# TC37XPD register map
Vendor: Infineon; Series: ATVMC; File version: 100
CPU: other r0p0, little endian, MPU, FPU, vendor SysTick, 4 interrupt priority bits
Registers are 32-bit, read-write, reset 0x0 unless marked. A register's access mark holds for its fields unless they carry their own. Offsets are from the block's base; [hi:lo] are bit positions; lines under a group give offsets from that group; {n}, {i} and the like mark numbered series.

## GTM (part 5 of 13)
Base 0xF0100000
0x28000 DPLL group
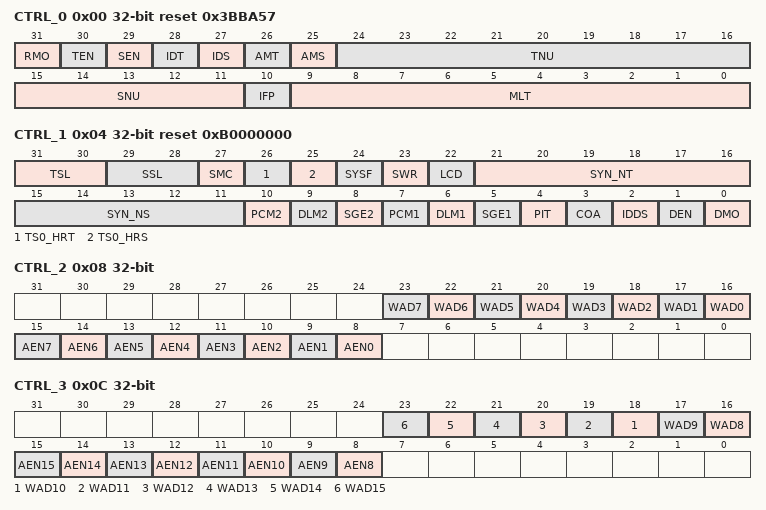
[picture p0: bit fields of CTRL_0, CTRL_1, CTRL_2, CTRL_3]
  0x00 CTRL_0 reset 0x3BBA57 — DPLL Control Register 0 resetvalue={Application Reset:0x3BBA57}
    [31] RMO — Reference mode. CROSSREFERENCE CROSSREFERENCE Selection of the relevant input signal for generation of SUB INC1. Double synchronous mode for SMC 1 Signal TRIGGER is used to generate the SUB INC1 signals and STATE is used to generate the SUB INC2 signals. Note For SMC 0 TRIGGER and STATE are prepared to calculate SUB INC1. The RMO bit gives a decision only which of them is used. For changing from normal mode to emergency mode at the following TRIGGER slope according to the RMO value in the shadow register CROSSREFERENCE the PSSC value is calculated by PSSC PSSM correction value forward direction or PSSC PSSM correction value backward direction with the correction value inc cnt1 nmb t. For changing from emergency mode to normal mode at the following STATE slope according to the RMO value in the shadow register CROSSREFERENCE the PSTC value is calculated by PSTC PSTM correction value forward direction or PSTC PSTM correction value backward direction with the correction value inc cnt1 nmb s. In case no further TRIGGER or STATE events the CPU has to perform the above corrections.
    [30] TEN — TRIGGER enable
    [29] SEN — STATE enable
    [28] IDT — Input delay TRIGGER. CROSSREFERENCE Use of input delay information transmitted in FT part of the TRIGGER signal.
    [27] IDS — Input delay STATE. CROSSREFERENCE Use of input delay information transmitted in FT part of the STATE signal.
    [26] AMT — Adapt mode TRIGGER. CROSSREFERENCE Use of adaptation information of TRIGGER.
    [25] AMS — Adapt mode STATE. CROSSREFERENCE Use of adaptation information of STATE.
    [24:16] TNU — TRIGGER number. CROSSREFERENCE TNU 1 is number of nominal TRIGGER events in HALF SCALE 1...512 . Note The number of nominal TRIGGER events is the decimal value plus 1.This value can only be written when RMO 1 and SMC 0 or DEN 0. To make sure that this signal is not changed during a mode change RMO 0 means that the status of RMO 0 must be given before and during writing to the register. Set TSL 00 before changing this value and set RMO 0 only after FULL SCALE with TSL gt 0.
    [15:11] SNU — STATE number. For IFP 1 the time between two active TRIGGER or STATE events must be always greater then 2.34 ms and the value x of MLT MLS1 or MLS2 must be chosen such that the number of time stamp pulses between two SUB INC events must be less than 65536. This is fulfilled when x is greater than 256. SNU 1 is number of nominal STATE events in HALF SCALE 1...32 . The number of nominal STATE events is the decimal value plus 1. This value can only be written when RMO 0 and SMC 0 or DEN 0. To make sure that this signal is not changed during a mode change RMO 0 means that the status of RMO 0 must be given before and during writing to the register. Set SSL 00 before changing this value and set RMO 1 only after FULL SCALE with SSL gt 0. This register can only be written when DPLL CTRL 11.STATE EXT is not set. If DPLL CTRL 11.STATE EXT is set the signal cannot be written the read value is zero.
    [10] IFP — Input filter position. CROSSREFERENCE stored in an independent shadow register for an active STATE event and for DEN 1. T he time between two active STATE or TRIGGER events must be always greater then 23.4 181 s in addition the TS CLK and the resolution must be chosen such that for each nominal increment the time stamps at the beginning and the end of the increment differ at least in the value of 257. Value contains position or time related information.
    [9:0] MLT — Multiplier for TRIGGER. stored in an independent shadow register for an active TRIGGER event and for DEN 1. MLT 1 is number of SUB INC1 pulses between two TRIGGER events in normal mode 1...1024 Note For emergency mode the number of SUB INC1 pulses between two STATE events is calculated by the CPU using the formula MLS1 MLT 1 TNU 1 SNU 1 in order to get the same number of SUB INC1 pulses for FULL SCALE. This value is stored in RAM at 0x05C0. Change of MLT by the CPU must result in the corresponding change of MLS1 by the CPU for SMC 0. Note The number of MLT events is the binary value plus 1. The value MLT 1 is replaced by MLS1 in the case of SMC 1 see DPLL CTRL 1 register for all relevant calculations.
  0x04 CTRL_1 reset 0xB0000000 — DPLL Control Register 1 resetvalue={Application Reset:0x0B0000000}
    [31:30] TSL — TRIGGER slope select. Definition of active slope for signal TRIGGER each active slope is an event defined by TNU. Set by DEN 0 only. If DPLL STATUS.FTD 1 slope sensitive after detection of first TRIGGER input signal If DPLL STATUS.FTD 0 level sensitive for first TRIGGER input signal edge Note This value can only be written when RMO 1 and SMC 0 or DEN 0. To make sure that this signal is not changed during a mode change SMC 0 means that the status of SMC 0 must be given before and during writing to the register.
    [29:28] SSL — STATE slope select. Definition of active slope for signal STATE each active slope is an event defined by SNU. Set by DEN 0 only. If DPLL STATUS.FSD 1 Slope sensitive after detection of first STATE input signal. If DPLL STATUS.FSD 0 8217 Level sensitive for first STATE input signal edge. This value can only be written when RMO 0 and SMC 0 or DEN 0. To make sure that this signal is not changed during a mode change SMC 0 means that the status of SMC 0 must be given before and during writing to the register.
    [27] SMC — Synchronous Motor Control. This bit can only be written when the DPLL is disabled.
    [26] TS0_HRT — Time stamp high resolution TRIGGER. This bit can only be written when the DPLL is disabled.
    [25] TS0_HRS — Time stamp high resolution STATE. This bit can only be written when the DPLL is disabled.
    [24] SYSF — SYN NS for FULL SCALE. The value SYN NS does mean the sum of all systematic missing STATE events in HALF SCALE for SYSF 0 or FULL SCALE for SYSF 1 . This value can only be written when RMO 0 and SMC 0 or DEN 0. Set SSL 00 before changing this value and set RMO 1 only after FULL SCALE with SSL gt 0. To make sure that this signal is not changed during a mode change SMC 0 means that the status of SMC 0 must be given before and during writing to the register.
    [23] SWR — Software reset. Resets all register and internal states of the DPLL. Setting the SWR bit results only in a software reset when the DPLL is not enabled DEN 0 .
    [22] LCD — Locking condition definition. This bit can only be written when the DPLL is disabled and fixed to zero when not needed for an implementation.
    [21:16] SYN_NT — Synchronization numberof TRIGGER. Summarized number of virtual increments in HALF SCALE. Sum of all systematic missing TRIGGER events in HALF SCALE the SYN NT missing TRIGGER can be divided up to an arbitrary number of blocks. The pattern of events and missing events in FULL SCALE is shown in RAM region 2c as value NT in addition to the adapted values. The number of stored increments in FULL SCALE must be equal to 2 TNU SYN NT . This pattern is written by the CPU beginning from a fixed reference point maybe beginning of the FULL SCALE region . The relation to the actual increment is established by setting of the profile RAM pointer APT 2C in an appropriate relation to the RAM pointer APT of the actual increment by the CPU. This value can only be written when RMO 1 and SMC 0 or DEN 0. Set TSL 00 before changing this value and set RMO 0 only after FULL SCALE with TSL gt 0. To make shure that this signal is not changed during a mode change SMC 0 means that the status of SMC 0 must be given before and during writing to the register.
    [15:11] SYN_NS — Synchronization number of STATE. Summarized number of virtual increments in HALF SCALE. Sum of all systematic missing STATE events in HALF SCALE for SYSF 0 or FULL SCALE for SYSF 1 the SYN NS missing STATES can be divided up to an arbitrary number of blocks. The pattern of events and missing events in FULL SCALE is shown in RAM region 1c3 as value NS in addition to the adapted values. The number of stored increments in FULL SCALE must be equal to 2 SNU 1 SYN NS for SYSF 0 or 2 SNU 1 SYN NS for SYSF 1 . This pattern is written by the CPU beginning from a fixed reference point maybe beginning of the FULL SCALE region . The relation to the actual increment is established by setting of the profile RAM pointer APS 1C3 in an appropriate relation to the RAM pointer APS of the actual increment by the CPU. This value can only be written when RMO 0 and SMC 0 or DEN 0. Set SSL 00 before changing this value and set RMO 1 only after FULL SCALE with SSL gt 0. To make shure that this signal is not changed during a mode change SMC 0 means that the status of SMC 0 must be given before and during writing to the register. This register can only be written when DPLL CTRL 11.STATE EXT is not set. If DPLL CTRL 11.STATE EXT is set the signal cannot be written the read value is zero.
    [10] PCM2 — Pulse Correction Mode for SUB INC2 generation. CROSSREFERENCE CROSSREFERENCE
    [9] DLM2 — Direct Load Mode for SUB INC2 generation. CROSSREFERENCE
    [8] SGE2 — SUB INC2 generator enable. CROSSREFERENCE
    [7] PCM1 — Pulse Correction Mode for SUB INC1 generation. CROSSREFERENCE CROSSREFERENCE Bit is cleared when transmitted to shadow register.
    [6] DLM1 — Direct Load Mode for SUB INC1 generation. CROSSREFERENCE CROSSREFERENCE
    [5] SGE1 — SUB INC1 generator enable. CROSSREFERENCE CROSSREFERENCE
    [4] PIT — Plausibility value PVT to next active TRIGGER is time related. CROSSREFERENCE
    [3] COA — Correction strategy in automatic end mode DMO 0 . CROSSREFERENCE CROSSREFERENCE For SMC RMO 1 COA is used for SUB INC1 and SUB INC2.
    [2] IDDS — Input direction detection strategy in the case of SMC 0. Note This bit can only be written when the DPLL is disabled and fixed to zero when not needed for an implementation. Independent of the value of IDDS is the direction information for TRIGGER in the case SMC 0 always considered at the moment when the inactive slope appears.
    [1] DEN — DPLL enable. Note The bits 31 down to 0 of the DPLL STATUS register are cleared when the DPLL is disabled. Some bits of the control registers can be set only when DEN 0. The protected bits in the DPLL CTRL 1 register cannot be written when simultaneously DEN is set to 1.
    [0] DMO — DPLL mode select. Stored in an independent shadow register for a valid TRIGGER event and for DEN 1. Stored in an independent shadow register for a valid STATE event and for DEN 1.
  0x08 CTRL_2 — DPLL Control Register 2 resetvalue={Application Reset:0x0}
    [n+16] WAD{n} (n=0..7) — Write control bit of Action 7. For WADx 1 only the corresponding AENx bits are writable. The AENx bits remain unchanged when the corresponding WADx 0.
    [n+8] AEN{n} (n=0..7) — ACTION 7 enable. This bit can be written only if the correspondent WADx bit is set in the same access. It can be set for debug purposes by CPU also when DPLL is disabled. The enable bit becomes active only when the DPLL is in operation DEN 1 . For WADi 1 only the corresponding AENi bits are writable. The AENi bits remain unchanged when the corresponding WADi 0.
  0x0C CTRL_3 — DPLL Control Register 3 resetvalue={Application Reset:0x0}
    [n+8] WAD{n} (n=8..15) — Write control bit of Action 15. For WADx 1 only the corresponding AENx bits are writable. The AENx bits remain unchanged when the corresponding WADx 0.
    [n] AEN{n} (n=8..15) — ACTION 15 enable. This bit can be written only if the correspondent WADx bit is set in the same access. It can be set for debug purposes by CPU also when DPLL is disabled. The enable bit becomes active only when the DPLL is in operation DEN 1 .
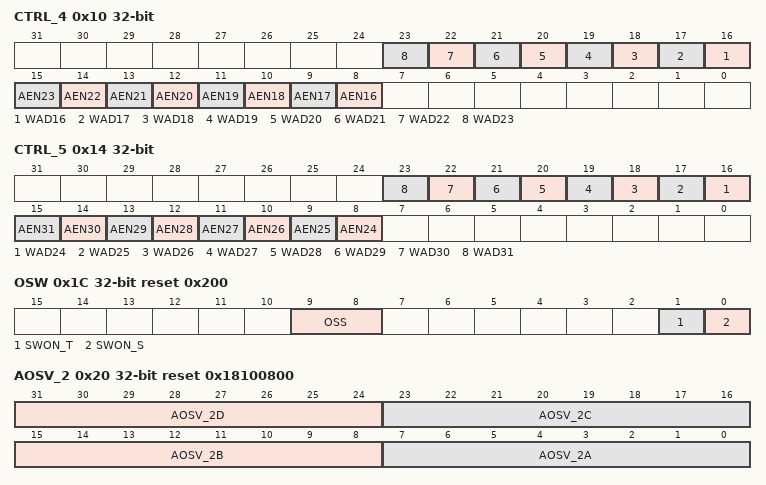
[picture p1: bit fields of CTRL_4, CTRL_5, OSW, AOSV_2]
  0x10 CTRL_4 — DPLL Control Register 4 resetvalue={Application Reset:0x0}
    [n] WAD{n} (n=16..23) — Write control bit of Action 23. For WADx 1 only the corresponding AENx bits are writable. The AENx bits remain unchanged when the corresponding WADx 0.
    [n-8] AEN{n} (n=16..23) — ACTION 23 enable. This bit can be written only if the correspondent WADx bit is set in the same access. It can be set for debug purposes by CPU also when DPLL is disabled. The enable bit becomes active only when the DPLL is in operation DEN 1 .
  0x14 CTRL_5 — DPLL Control Register 5 resetvalue={Application Reset:0x0}
    [n-8] WAD{n} (n=24..31) — Write control bit of Action 31. For WADx 1 only the corresponding AENx bits are writable. The AENx bits remain unchanged when the corresponding WADx 0.
    [n-16] AEN{n} (n=24..31) — ACTION 31 enable. This bit can be written only if the correspondent WADx bit is set in the same access. It can be set for debug purposes by CPU also when DPLL is disabled. The enable bit becomes active only when the DPLL is in operation DEN 1 .
  0x18 ACT_STA — DPLL ACTION Status Register with Connected Shadow Register resetvalue={Application Reset:0x0}
    [31:0] ACT_N — New output data values concerning to action i provided ACT N. ACT N i is Set for AENi 1 and a new valid PMTR that means when new action data are to be calculated for the correspondent action. After each calculation of the new actions values the ACT N i bit updates the corresponding bit in the connected shadow register. The status of the ACT N i bits in the shadow register is reflected by the corresponding DPLL output signal ACT V valid bit . Reset together with the corresponding shadow register bit for AENi 0. Reset without the corresponding shadow register bit when the calculated event is in the past the shadow register bit is set when it was not set before in that case . The corresponding shadow register bit is reset when new PMTR data are written or when the provided action data are read blocking read . Writeable for debugging purposes together with the corresponding shadow register when DEN 0. These bits can only be written for test purposes when the DPLL is disabled.
  0x1C OSW access per field reset 0x200 — DPLL Offset and Switch Old New Address Register resetvalue={Application Reset:0x200}
    [9:8] OSS rw — Offset size of RAM region 2. At least 128 and at most 1024 values can be stored in each of the RAM 2 regions a to d accordingly. The value can be set only for DEN 0. The change of the OSS value results in an automatic change of the offset values in the DPLL AOSV 2 register. This value can only be written when the DPLL is disabled.
    [1] SWON_T ro — Switch of new TRIGGER. Switch bit for LSB address of TRIGGER. This bit is changed for each write access to TS T TS T OLD. Using this unchanged address bit SWON T for any access to TS T results always in an access to TS T OLD. For writing to this address the former old TS T OLD old value is overwritten by the new one while the SWON T bit changes. Thus the former new one is now the old one and the next access is after changing SWON T directed to this place. Therefore write to TS T first and after that immediately to FTV T and PSTM always before a new TS T value is to be written. After writing TS T FTV T and PSTM in this order the address pointer AP with LSB AP SWON T shows for the corresponding address to TS T OLD FTV T and PSTM while LSB AP SWON T results in an access to TS T FTV T old and PSTM OLD respectively. The value can be read only. This bit is reset when disabling the DPLL DEN 0 .
    [0] SWON_S ro — Switch of new STATE. Switch bit for LSB address of STATE. This bit is changed for each write access to TS S TS S OLD. Using this unchanged address bit SWON S for any access to TS S results always in an access to TS S OLD. For writing to this address the former old TS S OLD old value is overwritten by the new one while the SWON S bit changes. Thus the former new one is now the old one and the next access is after changing SWON S directed to this place. Therefore write to TS S first and after that immediately to FTV S and PSSM always before a new TS S value is to be written. After writing TS S FTV S and PSSM in this order the address pointer AP with LSB AP SWON S shows for the corresponding address to TS S OLD FTV S and PSSM while LSB AP SWON S results in an access to TS S FTV S old and PSSM OLD respectively. The value can be read only. This bit is reset when disabling the DPLL DEN 0 .
  0x20 AOSV_2 ro reset 0x18100800 — DPLL Address Offset Register of RAM 2 Regions resetvalue={Application Reset:0x18100800}
    [31:24] AOSV_2D — Address offset value of the RAM 2D region AOSV 2D. The value in this field is to be multiplied by 256 shift left 8 Bits and added with the start address of the RAM in order to get the start address of RAM region 2d. When the APT value is added to this start address the current RAM cell DT Tx is addressed. Value is set automatically when OSS in the PPLL OSW register is set OSS 0x0 AOSV 2D 0x06 OSS 0x1 AOSV 2D 0x0C OSS 0x2 AOSV 2D 0x18 OSS 0x3 AOSV 2D 0x30 The offset values are needed to support a scalable RAM size of region 2 from 1 5 Kbytes to 12 Kbytes. The values above must be in correlation with the offset size defined in the OSW register. All offset values are set automatically in accordance to the OSS value in the DPLL OSW register. This value can be set only for DEN 0.
    [23:16] AOSV_2C — Address offset value of the RAM 2C region. The value in this field is to be multiplied by 256 shift left 8 Bits and added with the start address of the RAM in order to get the start address of RAM region 2c. When the APT value is added to this start address the current RAM cell ADT Tx is addressed. Value is set automatically when OSS in the PPLL OSW register is set OSS 0x0 AOSV 2C 0x04 OSS 0x1 AOSV 2C 0x08 OSS 0x2 AOSV 2C 0x10 OSS 0x3 AOSV 2C 0x20
    [15:8] AOSV_2B — Address offset value of the RAM 2B region. The value in this field is to be multiplied by 256 shift left 8 Bits and added with the start address of the RAM in order to get the start address of RAM region 2b. When the APT value is added to this start address the current RAM cell TSF Tx is addressed. Value is set automatically when OSS in the PPLL OSW register is set OSS 0x0 AOSV 2B 0x02 OSS 0x1 AOSV 2B 0x04 OSS 0x2 AOSV 2B 0x08 OSS 0x3 AOSV 2B 0x10
    [7:0] AOSV_2A — Address offset value of the RAM 2A region. The value in this field is to be multiplied by 256 shift left 8 Bits and added with the start address of the RAM in order to get the start address of RAM region 2a. When the APT value is added to this start address the current RAM cell RDT Tx is addressed. Value is set automatically when OSS in the PPLL OSW register is set OSS 0x0 AOSV 2A 0x00 OSS 0x1 AOSV 2A 0x00 OSS 0x2 AOSV 2A 0x00 OSS 0x3 AOSV 2A 0x00
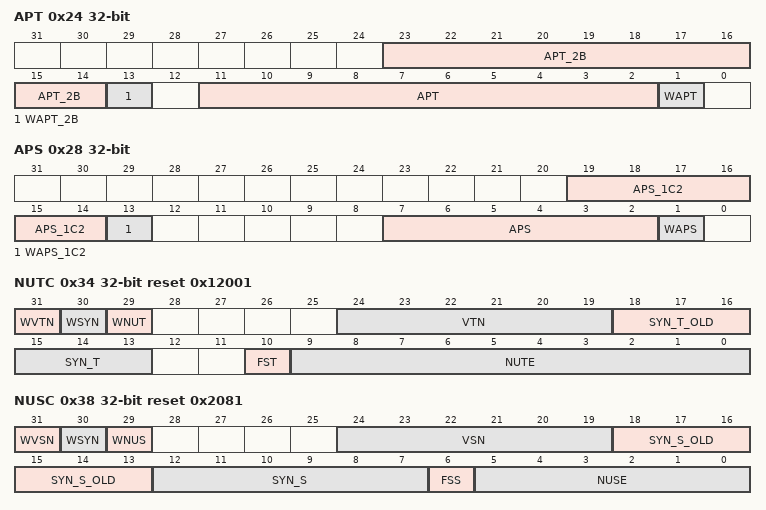
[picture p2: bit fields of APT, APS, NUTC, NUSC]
  0x24 APT — DPLL Actual RAM Pointer Address for TRIGGER resetvalue={Application Reset:0x0}
    [23:14] APT_2B — Address pointer TRIGGER for RAM region 2b. Actual RAM pointer address value for TSF T i Actual RAM pointer address of TRIGGER events in FULL SCALE for 2 TNU 1 TRIGGER periods this pointer is used for the RAM region 2b. The RAM pointer is initially set to zero. For SYT 1 The pointer APT 2B is incremented by SYN T OLD for each active TRIGGER event simultaneously with APT and APT 2C for DIR1 0 when an active TRIGGER input appears. For DIR1 1 backwards the APT is decremented by SYN T OLD. For SYT 0 APT 2B is incremented or decremented by 1. In addition when the APT 2C value is written by the CPU in order to synchronize the DPLL with the next active TRIGGER event the APT 2B EXT value is added subtracted while APT 2B STATUS is one see DPLL APT SYNC register at CROSSREFERENCE . This value can only be written when the WAPT 2B bit is set.
    [13] WAPT_2B — Write bit for address pointer APT 2B. Read as zero.
    [11:2] APT — Address pointer TRIGGER. Actual RAM pointer address value offset for DT T i and RDT T i in FULL SCALE for 2 TNU 1 SYN NT TRIGGER events. This pointer is used for the RAM region 2 subsections 2a and 2d. The pointer APT is incremented for each active TRIGGER event simultaneously with APT 2B APT 2C for DIR1 0. For DIR1 1 the APT is decremented. The APT offset value is added in the above shown bit position with the subsection address offset of the corresponding RAM region The APT pointer value is directed to the RAM position in which the data values are to be written which corresponds to the last increment. The APT value is not to be changed when the direction shown by DIR1 changes because it points always to a storage place after the considered increment. Changing of DIR1 takes place always after an active TRIGGER event and the resulting increment decrement. This value can only be written when the WAPT bit is set.
    [1] WAPT — Write bit for address pointer APT. Read as zero.
  0x28 APS — DPLL Actual RAM Pointer Address for STATE resetvalue={Application Reset:0x0}
    [19:14] APS_1C2 — Address pointer STATE for RAM region 1c2. Actual RAM pointer address value for TSF S i . Initial value zero 0x00 . Actual RAM pointer and synchronization position value of STATE events in FULL SCALE for up to 64 STATE events but limited to 2 SNU 1 in normal and emergency mode this pointer is used for the RAM region 1c2. For SYS 1 APS 1C2 is incremented decremented by SYN S OLD for each active STATE event and DIR2 0 DIR2 1 . For SYS 0 APT 1c2 is incremented or decremented by 1 respectively. The APS 1C2 offset value is added in the above shown bit position with the subsection offset of the RAM region. In addition when the APS 1C3 value is written by the CPU in order to synchronize the DPLL with the next active STATE event the APS 1C2 EXT value is added subtracted while APS 1C2 STATUS is one see DPLL APT SYNC register at CROSSREFERENCE . This value can only be written when the WAPS 1C2 bit is set
    [13] WAPS_1C2 — Write bit for address pointer APS 1C2. Read as zero
    [7:2] APS — Address pointer STATE. Actual RAM pointer address value for DT S i and RDT S i Actual RAM pointer and synchronization position value of STATE events in FULL SCALE for up to 64 STATE events but limited to 2 SNU 1 SYN NS in normal and emergency mode for SYSF 0 or to 2 SNU 1 SYN NS for SYSF 1 respectively this pointer is used for the RAM region 1c1 and 1c4. APS is incremented decremented by one for each active STATE event and DIR2 0 DIR2 1 . The APS offset value is added in the above shown bit position with the subsection offset of the RAM region. The APS pointer value is directed to the RAM position in which the data values are to be written which correspond to the last increment. The APS value is not to be changed when the direction shown by DIR2 changes because it points always to a storage place after the considered increment. Changing of DIR2 takes place always after an active STATE event and the resulting increment decrement. This value can only be written when the WAPS bit is set.
    [1] WAPS — Write bit for address pointer APS. Read as zero
  0x2C APT_2C — DPLL Actual RAM Pointer for Region 2C resetvalue={Application Reset:0x0}
    [11:2] APT_2C — Address pointer TRIGGER for RAM region 2c and Actual RAM pointer address value for ADT T i . Actual RAM pointer address value of TRIGGER adapt events in FULL SCALE for 2 TNU 1 SYN NT TRIGGER periods depending on the size of the used RAM 2 this pointer is used for the RAM region 2 for the subsection 2c only. The RAM pointer is initially set to zero. The APT 2C value is set by the CPU when the synchronization condition was detected. Within the RAM region 2c initially the conditions for synchronization gaps and adapted values are stored by the CPU.
  0x30 APS_1C3 — DPLL Actual RAM Pointer for RAM Region 1C3 resetvalue={Application Reset:0x0}
    [7:2] APS_1C3 — Address pointer STATE for RAM region 1c3. Actual RAM pointer address value for ADT S i . Initial value zero 0x00 . Actual RAM pointer and synchronization position value of STATE events in FULL SCALE for up to 64 STATE events but limited to 2 SNU 1 SYN NS in normal and emergency mode for SYSF 0 or to 2 SNU 1 SYN NS for SYSF 1 respectively this pointer is used for the RAM region 1c3. The RAM pointer is set by the CPU accordingly when the synchronization condition was detected.
  0x34 NUTC reset 0x12001 — DPLL Number of Recent TRIGGER Events Used for Calculations resetvalue={Application Reset:0x12001}
    [31] WVTN — Write control bit for VTN. Read as zero
    [30] WSYN — Write control bit for SYN T and SYN T OLD. Read as zero
    [29] WNUT — Write control bit for NUTE and FST. Read as zero
    [24:19] VTN — Virtual TRIGGER number. Number of virtual increments in the current NUTE region This value reflects the number of virtual increments in the current NUTE region for NUTE 1 this value is zero when the CPU sets NUTE to a value gt 1 it must also set VTN to the correspondent value for NUTE is set to FULL SCALE including NUTE zero 2 11 modulo 2 11 the VTN is to be set to 2 SYN NT. The VTN value is subtracted from the NUTE value in order to get the corresponding APT value for the past the VTN value is not used for the APT 2B pointer. VTN is to be updated by the CPU when a new gap is to be considered for NUTE or a gap is leaving the NUTE region for this purpose the TINT values in the profile can be used to generate an interrupt for the CPU at the corresponding positions no further update of VTN is necessary when NUTE is set to FULL SCALE This value can only be written when the WVTN bit is set.
    [18:16] SYN_T_OLD — Number of real and virtual events to be considered for the last increment. This value reflects the NT value of the last but one valid increment stored in ADT T i is updated automatically when writing SYN T. This value is updated by the SYN T value when the WSYN bit in this register is set.
    [15:13] SYN_T — Number of real and virtual events to be considered for the current increment. This value reflects the NT value of the last valid increment stored in ADT T i to be updated after all calculations in step 17 of CROSSREFERENCE . This value can only be written when the WSYN bit in this register is set.
    [10] FST — FULL SCALE of TRIGGER. This value is to be set when NUTE is set to FULL SCALE. This value can only be written when the WNUT bit is set.
    [9:0] NUTE — Number of recent TRIGGER events used for SUB INC1 and action calculations modulo 2 TNUmax 1 . Number of recent TRIGGER events used for SUB INC1 and action calculations modulo 2 TNUmax 1 . NUTE number of last nominal increments to be considered for the calculations. No gap is considered in that case for this value but in the VTN value see below This value is set by the CPU but reset automatically to 1 by a change of direction or loss of LOCK. Each other value can be set by the CPU maybe Full SCALE HALF SCALE or parts of them. For FULL SCALE set NUTE 2 TNU 1 and for HALF SCALE NUTE TNU 1. The relation values QDT Tx are calculated using NUTE values in the past with its maximum value of 2 TNU 1 . The value zero in combination with the value FST 1 does mean 2 11 values in the past. Note To prevent that inconsistencies between internal pointer in which NUTE is used and the case decision of different prediction method s for prediction of the next event and PMT position minus time occur the NUTE value is stored internally at that point of time when the internal pointers are calculated for the next event cycle. Note This value can only be written when the WNUT bit is set.
  0x38 NUSC reset 0x2081 — DPLL Number of Recent STATE Events Used for Calculations resetvalue={Application Reset:0x2081}
    [31] WVSN — Write control bit for VS WVSN. Read as zero
    [30] WSYN — Write control bit for SYN S and SYN S OLD. Read as zero 0 the SYN S value is not writeable 1 the SYN S value is writeable
    [29] WNUS — Write control bit for NUSE. Read as zero. 0 the NUSE value is not writeable 1 the NUSE value is writeable
    [24:19] VSN — Virtual STATE number. Number of virtual state increments in the current NUSE region. This value reflects the number of virtual increments in the current NUSE region for NUSE 1 this value is zero when the CPU sets NUSE to a value gt 1 or zero 2 7 modulo 2 7 it must also set VSN to the correspondent value the VSN value is subtracted from the NUSE value in order to get the corresponding APS value for the past the VSN value is not used for the APS 1C2 pointer. VSN is to be updated by the CPU when a new gap is to be considered for NUSE or a gap is leaving the NUSE region for this purpose the SASI interrupt can be used no further update of VSN is necessary when NUSE is set to FULL SCALE This value can only be written when the WVSN bit is set.
    [18:13] SYN_S_OLD — Number of real and virtual events to be considered for the last increment. This value reflects the NS value of the last but one valid increment stored in ADT S i is updated automatically when writing SYN S. This value is updated by the SYN S value when the WSYN bit in this register is set.
    [12:7] SYN_S — Number of real and virtual events to be considered for the current increment. This value reflects the NS value of the last valid increment stored in ADT S i to be updated after all calculations in step 37 of CROSSREFERENCE . This value can only be written when the WSYN bit in this register is set.
    [6] FSS — FULL SCALE of STATE. This value is to be set when NUSE is set to FULL SCALE. This value is set by the CPU but reset automatically to 0 by a change of direction or loss of LOCK. Note This value can only be written when the WNUS bit is set.
    [5:0] NUSE — Number of recent STATE events used for SUB INCx calculations modulo 2 SNUmax 1 . No gap is considered in that case for this value but in the VSN value see below This register is set by the CPU but reset automatically to x201c 1 x201d by a change of direction or loss of LOCK. Each other value can be set by the CPU maybe Full SCALE HALF SCALE or parts of them. The relation values QDT Sx are calculated using NUSE values in the past with its maximum value of 2 SNU 1. This value can only be written when the WNUS bit is set. Note To prevent that inconsistencies between internal pointer in which NUSE is used and the case decision of different prediction method s for prediction of the next event and PMT position minus time occur the NUSE value is stored internally at that point of time when the internal pointers are calculated for the next event cycle.
  0x3C NTI_CNT — DPLL Number of Active TRIGGER Events to Interrupt resetvalue={Application Reset:0x0}
    [9:0] NTI_CNT — Number of TRIGGERs to interrupt. Number of active TRIGGER events to the next DPLL CDTI interrupt. This value shows the remaining TRIGGER events until an active TRIGGER slope results in a DPLL CDTI interrupt the value is to be count down for each active TRIGGER event.
  0x40 IRQ group
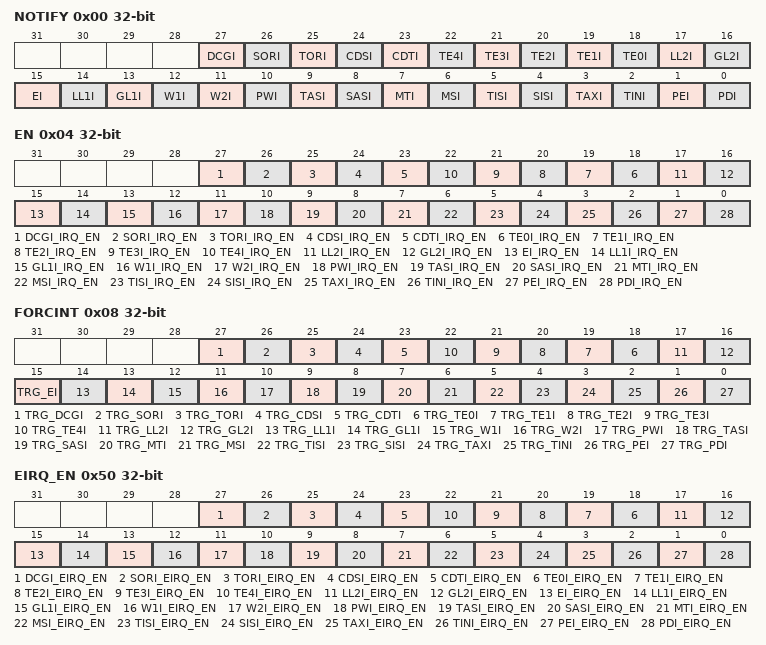
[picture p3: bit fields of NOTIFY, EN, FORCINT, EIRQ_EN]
    0x00 NOTIFY — DPLL Interrupt Notification Register resetvalue={Application Reset:0x0}
      [27] DCGI — Direction change interrupt
      [26] SORI — STATE out of range. The interrupt occurs at line number 0.
      [25] TORI — TRIGGER out of range interrupt
      [24] CDSI — Calculation of STATE duration done
      [23] CDTI — Calculation of TRIGGER duration done only while NTI CNT is zero
      [n+18] TE{n}I (n=0..4) — TRIGGER event interrupt {n}
      [17] LL2I — Loss of lock interrupt for SUB INC2
      [16] GL2I — Get of lock interrupt for SUB INC2
      [15] EI — Error interrupt see status register bit 31
      [14] LL1I — Loss of lock interrupt for SUB INC1
      [13] GL1I — Get of lock interrupt for SUB INC1
      [12] W1I — Write access to RAM region 1b or 1c interrupt
      [11] W2I — RAM write access to RAM region 2 interrupt
      [10] PWI — Plausibility window PVT violation interrupt of TRIGGER
      [9] TASI — TRIGGER active slope interrupt
      [8] SASI — STATE active slope interrupt
      [7] MTI — Missing TRIGGER interrupt
      [6] MSI — Missing STATE interrupt
      [5] TISI — TRIGGER inactive slope interrupt. The TISI bit is only set for an inactive slope when the preceding active slope was accepted. In the case of suppression of the last active slope by the plausibility check the next inactive slope is to be ignored. No set of TISI is performed in this case.
      [4] SISI — STATE inactive slope interrupt
      [3] TAXI — TRIGGER maximum hold time violation interrupt dt THMA 0
      [2] TINI — TRIGGER minimum hold time violation interrupt dt THMI 0
      [1] PEI — DPLL enable interrupt. Announces the switch on of the DEN bit. This event is combined with the PDI interrupt to the common PDI PEI interrupt line number 1.
      [0] PDI — DPLL disable interrupt announces the switch off of the DEN bit. This event is combined with the PEI interrupt to the common PDI PEI interrupt line number 1.
    0x04 EN — DPLL Interrupt Enable Register resetvalue={Application Reset:0x0}
      [27] DCGI_IRQ_EN — Direction change interrupt enable
      [26] SORI_IRQ_EN — STATE out of range interrupt enable
      [25] TORI_IRQ_EN — TRIGGER out of range interrupt enable
      [24] CDSI_IRQ_EN — Interrupt enable for calculation of STATE duration done
      [23] CDTI_IRQ_EN — Interrupt enable for calculation of TRIGGER duration done
      [n+18] TE{n}I_IRQ_EN (n=0..4) — TRIGGER event interrupt {n} enable
      [17] LL2I_IRQ_EN — Loss of lock interrupt enable for SUB INC2
      [16] GL2I_IRQ_EN — Get of lock interrupt enable for SUB INC2
      [15] EI_IRQ_EN — Error interrupt enable see status register
      [14] LL1I_IRQ_EN — Loss of lock interrupt enable
      [13] GL1I_IRQ_EN — Get of lock interrupt enable when lock arises
      [12] W1I_IRQ_EN — Write access to RAM region 1b or 1c interrupt enable
      [11] W2I_IRQ_EN — RAM write access to RAM region 2 interrupt enable
      [10] PWI_IRQ_EN — Plausibility window PVT violation of TRIGGER interrupt enable
      [9] TASI_IRQ_EN — TRIGGER active slope interrupt enable
      [8] SASI_IRQ_EN — STATE active slope interrupt enable
      [7] MTI_IRQ_EN — Missing TRIGGER interrupt enable
      [6] MSI_IRQ_EN — Missing STATE interrupt enable
      [5] TISI_IRQ_EN — TRIGGER inactive slope interrupt enable
      [4] SISI_IRQ_EN — STATE inactive slope interrupt enable
      [3] TAXI_IRQ_EN — TRIGGER maximum hold time violation interrupt enable
      [2] TINI_IRQ_EN — TRIGGER minimum hold time violation interrupt enable
      [1] PEI_IRQ_EN — DPLL enable interrupt enable when switch on of the DEN bit
      [0] PDI_IRQ_EN — DPLL disable interrupt enable when switch off of the DEN bit
    0x08 FORCINT — DPLL Interrupt Force Register resetvalue={Application Reset:0x0}
      [27] TRG_DCGI — Force interrupt DCGI. Coding see bit 0.
      [26] TRG_SORI — Force Interrupt SORI. Coding see bit 0.
      [25] TRG_TORI — Force Interrupt TORI. Coding see bit 0.
      [24] TRG_CDSI — Force Interrupt CDSI. Coding see bit 0.
      [23] TRG_CDTI — Force Interrupt CDTI. Coding see bit 0.
      [n+18] TRG_TE{n}I (n=0..4) — Force Interrupt TE{n}I. Coding see bit 0.
      [17] TRG_LL2I — Force Interrupt LL2I. Coding see bit 0.
      [16] TRG_GL2I — Force Interrupt GL2I. Coding see bit 0.
      [15] TRG_EI — Force Interrupt EI. Coding see bit 0.
      [14] TRG_LL1I — Force Interrupt LL1I. Coding see bit 0.
      [13] TRG_GL1I — Force Interrupt GL1I. Coding see bit 0.
      [12] TRG_W1I — Force Interrupt W1I. Coding see bit 0.
      [11] TRG_W2I — Force Interrupt W2I. Coding see bit 0.
      [10] TRG_PWI — Force Interrupt PWI. Coding see bit 0.
      [9] TRG_TASI — Force Interrupt TASI. Coding see bit 0.
      [8] TRG_SASI — Force Interrupt SASI. Coding see bit 0.
      [7] TRG_MTI — Force Interrupt MTI. Coding see bit 0.
      [6] TRG_MSI — Force Interrupt MSI. Coding see bit 0.
      [5] TRG_TISI — Force Interrupt TISI. Coding see bit 0.
      [4] TRG_SISI — Force Interrupt SISI. Coding see bit 0.
      [3] TRG_TAXI — Force Interrupt TAXI. Coding see bit 0.
      [2] TRG_TINI — Force Interrupt TINI. Coding see bit 0.
      [1] TRG_PEI — Force Interrupt PEI. Coding see bit 0.
      [0] TRG_PDI — Force Interrupt PDI. This bit is cleared automatically after write. This bit is write protected by bit RF PROT of register GTM CTRL.
    0x0C MODE — DPLL Interrupt Mode Register resetvalue={Application Reset:0x0}
      [1:0] IRQ_MODE — IRQ mode selection. The interrupt modes are described in CROSSREFERENCE .
  0x50 EIRQ_EN — DPLL Error Interrupt Enable Register resetvalue={Application Reset:0x0}
    [27] DCGI_EIRQ_EN — Direction change interrupt
    [26] SORI_EIRQ_EN — STATE out of range
    [25] TORI_EIRQ_EN — TRIGGER out of range interrupt
    [24] CDSI_EIRQ_EN — Enable interrupt when calculation of TRIGGER duration done
    [23] CDTI_EIRQ_EN — Enable interrupt when calculation of TRIGGER duration done
    [n+18] TE{n}I_EIRQ_EN (n=0..4) — TRIGGER event interrupt {n} enable
    [17] LL2I_EIRQ_EN — Loss of lock interrupt enable for SUB INC2
    [16] GL2I_EIRQ_EN — Get of lock interrupt enable for SUB INC2
    [15] EI_EIRQ_EN — Error interrupt enable see status register
    [14] LL1I_EIRQ_EN — Loss of lock interrupt enable
    [13] GL1I_EIRQ_EN — Get of lock interrupt enable when lock arises
    [12] W1I_EIRQ_EN — Write access to RAM region 1b or 1c interrupt
    [11] W2I_EIRQ_EN — RAM write access to RAM region 2 interrupt enable
    [10] PWI_EIRQ_EN — Plausibility window PVT violation interrupt of TRIGGER enable
    [9] TASI_EIRQ_EN — TRIGGER active slope interrupt enable
    [8] SASI_EIRQ_EN — STATE active slope interrupt enable
    [7] MTI_EIRQ_EN — Missing TRIGGER interrupt enable
    [6] MSI_EIRQ_EN — Missing STATE interrupt enable
    [5] TISI_EIRQ_EN — TRIGGER inactive slope interrupt enable bit
    [4] SISI_EIRQ_EN — STATE inactive slope interrupt enable bit
    [3] TAXI_EIRQ_EN — TRIGGER maximum hold time violation interrupt enable bit
    [2] TINI_EIRQ_EN — TRIGGER minimum hold time violation interrupt enable bit
    [1] PEI_EIRQ_EN — DPLL enable interrupt enable when switch on of the DEN bit
    [0] PDI_EIRQ_EN — DPLL disable interrupt enable when switch off of the DEN bit
  0xB0 INC_CNT1 — DPLL Counter for Pulses for TBU CH1 BASE to be Sent in Automatic End Mode resetvalue={Application Reset:0x0}
    [23:0] INC_CNT1 — Actual number of pulses to be still sent out at the current increment until the next active input signal in automatic end mode. Automatic addition of the number of demanded pulses MLT MLS1 when getting an active TRIGGER STATE input in normal or emergency mode respectively when SGE1 1 writeable only for test purposes when DEN 0. In the case of a change of the direction the wrong number of pulses are corrected twice Add the difference between NMB T and INC CNT1 twice to INC CNT1 before sending out the correction pulses. This value can only be written when the DPLL is disabled.
